AUTOSAR XML (schema 4.0)
standard types defined: float32, float64, sint16, sint32, sint8, uint16, uint32, uint8, void, boolean
package /ImplDataTypes
  7 x impl type, all with category=TYPE_REFERENCE, type-emitter=RTE:
    IoPositionSensorReadingType: implementation-data-type=uint8
    IoWeightSensorReadingType: implementation-data-type=uint16
    MultiStateBtnType: implementation-data-type=uint8
    SeatModeBtnType: implementation-data-type=uint8
    SensorPositionType: implementation-data-type=uint8
    SensorWeightType: implementation-data-type=uint8
    StepMotorStepType: implementation-data-type=uint8
package /MappingSets
  data type mapping set MappingSet: mode-request-type-map{implementation-data-type=uint8, mode-group=SeatCtrlMode}
package /PortInterfaces/ClientServer
  6 x client server interface:
    CsIf_IoGetSensorPosition
      operation IOGet
        arg IOPosition: type=IoPositionSensorReadingType, direction=OUT
    CsIf_IoGetSensorWeight
      operation IOGet
        arg IOWeight: type=IoWeightSensorReadingType, direction=OUT
    CsIf_IoSetMotor
      operation IOSetForward
      operation IOSetReverse
    CsIf_PositionSensor
      operation GetPosition
        arg Position: type=SensorPositionType, direction=OUT
    CsIf_StepMotor
      operation Move
        arg step: type=StepMotorStepType, direction=IN
    CsIf_WeightSensor
      operation GetWeight
        arg Weight: type=SensorWeightType, direction=OUT
package /PortInterfaces/ModeSwitch
  mode switch interface MsIf_SeatCtrlMode
    mode group SeatCtrlMode: type=SeatCtrlMode
  mode declaration group SeatCtrlMode: category=ALPHABETIC_ORDER, initial-mode=INIT, on-transition-value=255
    mode AUTO
    mode INIT
    mode MANUAL
package /PortInterfaces/SenderReceiver
  sender receiver interface SrIf_SeatCtrlBtns
    data HeightBtnState: type=MultiStateBtnType
    data InclineBtnState: type=MultiStateBtnType
    data SlideBtnState: type=MultiStateBtnType
  sender receiver interface SrIf_SeatCtrlData
    data Height: type=uint8
    data Incline: type=uint8
    data Slide: type=uint8
  sender receiver interface SrIf_SeatModeBtn
    data SeatModeBtn: type=SeatModeBtnType
package /SoftwareComponents
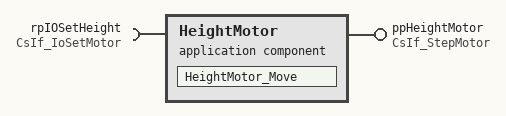
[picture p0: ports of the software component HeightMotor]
  application sw component type HeightMotor
    provide port ppHeightMotor: provided-interface=CsIf_StepMotor
    require port rpIOSetHeight: required-interface=CsIf_IoSetMotor
    behavior Ibhv_HeightMotor: data-type-mapping=MappingSet, handle-termination-and-restart=NO-SUPPORT
      operation invoked event OIE_ppHeightMotor_Move: start-on-event=HeightMotor_Move, operation=ppHeightMotor.Move
      runnable HeightMotor_Move
        sync call SCP_rpIOSetHeight_IOSetForward: operation=rpIOSetHeight.IOSetForward, timeout=0.0
        sync call SCP_rpIOSetHeight_IOSetReverse: operation=rpIOSetHeight.IOSetReverse, timeout=0.0
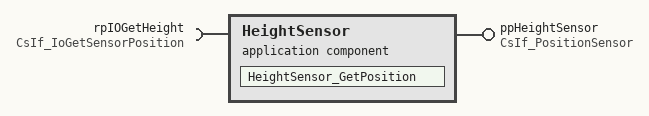
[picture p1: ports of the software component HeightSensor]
  application sw component type HeightSensor
    provide port ppHeightSensor: provided-interface=CsIf_PositionSensor
    require port rpIOGetHeight: required-interface=CsIf_IoGetSensorPosition
    behavior Ibhv_HeightSensor: data-type-mapping=MappingSet, handle-termination-and-restart=NO-SUPPORT
      operation invoked event OIE_ppHeightSensor_GetPosition: start-on-event=HeightSensor_GetPosition, operation=ppHeightSensor.GetPosition
      runnable HeightSensor_GetPosition
        sync call SCP_rpIOGetHeight_IOGet: operation=rpIOGetHeight.IOGet, timeout=0.0
  10 x swc implementation, all with programming-language=C, sw-version=1.0.0, vendor-id=255:
    Impl_HeightMotor: behavior=Ibhv_HeightMotor
      code-descriptors:
        code Code: artifact-descriptors=autosar-engineering-object={short-label=SWC.c, category=SWSRC}
      resource consumption ResourceConsumption
    Impl_HeightSensor: behavior=Ibhv_HeightSensor
      code-descriptors:
        code Code: artifact-descriptors=autosar-engineering-object={short-label=SWC.c, category=SWSRC}
      resource consumption ResourceConsumption
    Impl_InclineMotor: behavior=Ibhv_InclineMotor
      code-descriptors:
        code Code: artifact-descriptors=autosar-engineering-object={short-label=SWC.c, category=SWSRC}
      resource consumption ResourceConsumption
    Impl_InclineSensor: behavior=Ibhv_InclineSensor
      code-descriptors:
        code Code: artifact-descriptors=autosar-engineering-object={short-label=SWC.c, category=SWSRC}
      resource consumption ResourceConsumption
    Impl_IoHwAbs: behavior=Ibhv_IoHwAbs
      code-descriptors:
        code Code: artifact-descriptors=autosar-engineering-object={short-label=SWC.c, category=SWSRC}
      resource consumption ResourceConsumption
    Impl_SWC_HMI: behavior=Ibhv_SWC_HMI
      code-descriptors:
        code Code: artifact-descriptors=autosar-engineering-object={short-label=SWC.c, category=SWSRC}
      resource consumption ResourceConsumption
    Impl_SWC_SeatMngr: behavior=Ibhv_SWC_SeatMngr
      code-descriptors:
        code Code: artifact-descriptors=autosar-engineering-object={short-label=SWC.c, category=SWSRC}
      resource consumption ResourceConsumption
    Impl_SlideMotor: behavior=Ibhv_SlideMotor
      code-descriptors:
        code Code: artifact-descriptors=autosar-engineering-object={short-label=SWC.c, category=SWSRC}
      resource consumption ResourceConsumption
    Impl_SlideSensor: behavior=Ibhv_SlideSensor
      code-descriptors:
        code Code: artifact-descriptors=autosar-engineering-object={short-label=SWC.c, category=SWSRC}
      resource consumption ResourceConsumption
    Impl_WeightSensor: behavior=Ibhv_WeightSensor
      code-descriptors:
        code Code: artifact-descriptors=autosar-engineering-object={short-label=SWC.c, category=SWSRC}
      resource consumption ResourceConsumption
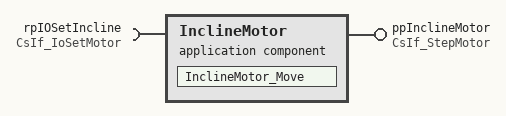
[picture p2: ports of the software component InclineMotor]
  application sw component type InclineMotor
    provide port ppInclineMotor: provided-interface=CsIf_StepMotor
    require port rpIOSetIncline: required-interface=CsIf_IoSetMotor
    behavior Ibhv_InclineMotor: data-type-mapping=MappingSet, handle-termination-and-restart=NO-SUPPORT
      operation invoked event OIE_ppInclineMotor_Move: start-on-event=InclineMotor_Move, operation=ppInclineMotor.Move
      runnable InclineMotor_Move
        sync call SCP_rpIOSetIncline_IOSetForward: operation=rpIOSetIncline.IOSetForward, timeout=0.0
        sync call SCP_rpIOSetIncline_IOSetReverse: operation=rpIOSetIncline.IOSetReverse, timeout=0.0
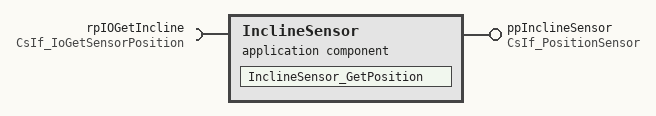
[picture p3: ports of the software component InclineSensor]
  application sw component type InclineSensor
    provide port ppInclineSensor: provided-interface=CsIf_PositionSensor
    require port rpIOGetIncline: required-interface=CsIf_IoGetSensorPosition
    behavior Ibhv_InclineSensor: data-type-mapping=MappingSet, handle-termination-and-restart=NO-SUPPORT
      operation invoked event OIE_ppInclineSensor_GetPosition: start-on-event=InclineSensor_GetPosition, operation=ppInclineSensor.GetPosition
      runnable InclineSensor_GetPosition
        sync call SCP_rpIOGetIncline_IOGet: operation=rpIOGetIncline.IOGet, timeout=0.0
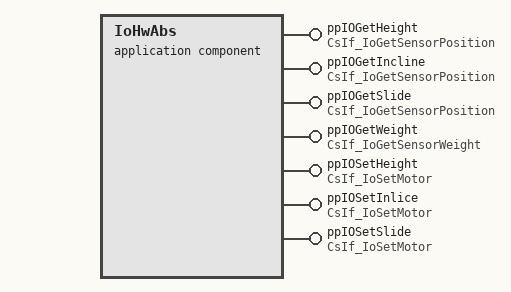
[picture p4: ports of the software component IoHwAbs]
  application sw component type IoHwAbs
    7 x provide port:
      ppIOGetHeight: provided-interface=CsIf_IoGetSensorPosition
      ppIOGetIncline: provided-interface=CsIf_IoGetSensorPosition
      ppIOGetSlide: provided-interface=CsIf_IoGetSensorPosition
      ppIOGetWeight: provided-interface=CsIf_IoGetSensorWeight
      ppIOSetHeight: provided-interface=CsIf_IoSetMotor
      ppIOSetInlice: provided-interface=CsIf_IoSetMotor
      ppIOSetSlide: provided-interface=CsIf_IoSetMotor
    behavior Ibhv_IoHwAbs: data-type-mapping=MappingSet, handle-termination-and-restart=NO-SUPPORT
      10 x operation invoked event:
        OIE_ppIOGetHeight_IOGet: start-on-event=IoHwAbs_ECUGetHeight, operation=ppIOGetHeight.IOGet
        OIE_ppIOGetIncline_IOGet: start-on-event=IoHwAbs_ECUGetIncline, operation=ppIOGetIncline.IOGet
        OIE_ppIOGetSlide_IOGet: start-on-event=IoHwAbs_ECUGetSlide, operation=ppIOGetSlide.IOGet
        OIE_ppIOGetWeight_IOGet: start-on-event=IoHwAbs_ECUGetWeight, operation=ppIOGetWeight.IOGet
        OIE_ppIOSetHeight_IOSetForward: start-on-event=IoHwAbs_ECUSetForward_Height, operation=ppIOSetHeight.IOSetForward
        OIE_ppIOSetHeight_IOSetReverse: start-on-event=IoHwAbs_ECUSetReverse_Height, operation=ppIOSetHeight.IOSetReverse
        OIE_ppIOSetInlice_IOSetForward: start-on-event=IoHwAbs_ECUSetForward_Incline, operation=ppIOSetInlice.IOSetForward
        OIE_ppIOSetInlice_IOSetReverse: start-on-event=IoHwAbs_ECUSetReverse_Incline, operation=ppIOSetInlice.IOSetReverse
        OIE_ppIOSetSlide_IOSetForward: start-on-event=IoHwAbs_ECUSetForward_Slide, operation=ppIOSetSlide.IOSetForward
        OIE_ppIOSetSlide_IOSetReverse: start-on-event=IoHwAbs_ECUSetReverse_Slide, operation=ppIOSetSlide.IOSetReverse
      10 x runnable:
        IoHwAbs_ECUGetHeight
        IoHwAbs_ECUGetIncline
        IoHwAbs_ECUGetSlide
        IoHwAbs_ECUGetWeight
        IoHwAbs_ECUSetForward_Height
        IoHwAbs_ECUSetForward_Incline
        IoHwAbs_ECUSetForward_Slide
        IoHwAbs_ECUSetReverse_Height
        IoHwAbs_ECUSetReverse_Incline
        IoHwAbs_ECUSetReverse_Slide
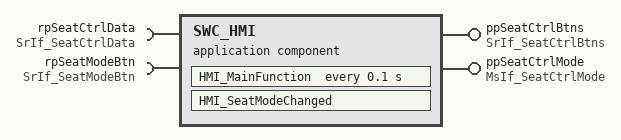
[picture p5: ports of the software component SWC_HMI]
  application sw component type SWC_HMI
    provide port ppSeatCtrlBtns: provided-interface=SrIf_SeatCtrlBtns
    provide port ppSeatCtrlMode: provided-interface=MsIf_SeatCtrlMode
    require port rpSeatCtrlData: required-interface=SrIf_SeatCtrlData
    require port rpSeatModeBtn: required-interface=SrIf_SeatModeBtn
    behavior Ibhv_SWC_HMI: data-type-mapping=MappingSet, handle-termination-and-restart=NO-SUPPORT
      data received event DRE_rpSeatModeBtn_SeatModeBtn: start-on-event=HMI_SeatModeChanged, data=rpSeatModeBtn.SeatModeBtn
      timing event TE_HMI_MainFunction_100ms: start-on-event=HMI_MainFunction, period=0.1
      runnable HMI_MainFunction
        data-receive-point-by-arguments:
          access DRP_rpSeatCtrlData_DE_Height: accessed-variable=rpSeatCtrlData.Height
          access DRP_rpSeatCtrlData_DE_Incline: accessed-variable=rpSeatCtrlData.Incline
          access DRP_rpSeatCtrlData_DE_Slide: accessed-variable=rpSeatCtrlData.Slide
        data-send-points:
          access DSP_ppSeatCtrlBtns_DE_HeightBtnState: accessed-variable=ppSeatCtrlBtns.HeightBtnState
          access DSP_ppSeatCtrlBtns_DE_InclineBtnState: accessed-variable=ppSeatCtrlBtns.InclineBtnState
          access DSP_ppSeatCtrlBtns_DE_SlideBtnState: accessed-variable=ppSeatCtrlBtns.SlideBtnState
      runnable HMI_SeatModeChanged
        data-receive-point-by-arguments:
          access DRP_rpSeatModeBtn_SeatModeBtn: accessed-variable=rpSeatModeBtn.SeatModeBtn
        mode switch point MSP_ppSeatCtrlMode_ppSeatCtrlMode: mode-group=ppSeatCtrlMode.SeatCtrlMode
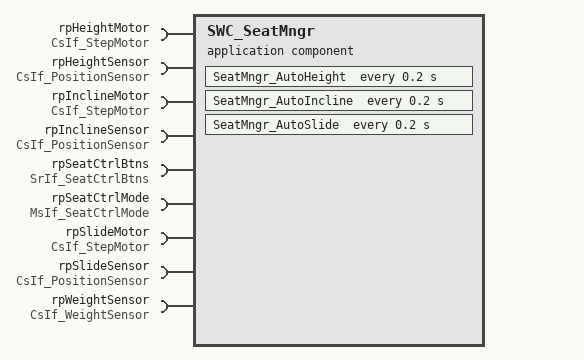
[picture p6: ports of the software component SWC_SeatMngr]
  application sw component type SWC_SeatMngr
    9 x require port:
      rpHeightMotor: required-interface=CsIf_StepMotor
      rpHeightSensor: required-interface=CsIf_PositionSensor
      rpInclineMotor: required-interface=CsIf_StepMotor
      rpInclineSensor: required-interface=CsIf_PositionSensor
      rpSeatCtrlBtns: required-interface=SrIf_SeatCtrlBtns
      rpSeatCtrlMode: required-interface=MsIf_SeatCtrlMode
      rpSlideMotor: required-interface=CsIf_StepMotor
      rpSlideSensor: required-interface=CsIf_PositionSensor
      rpWeightSensor: required-interface=CsIf_WeightSensor
    behavior Ibhv_SWC_SeatMngr: data-type-mapping=MappingSet, handle-termination-and-restart=NO-SUPPORT
      data received event DRE_rpSeatCtrlBtns_DE_HeightBtnState: start-on-event=SeatMngr_SetHeight, data=rpSeatCtrlBtns.DE_HeightBtnState
      data received event DRE_rpSeatCtrlBtns_DE_InclineBtnState: start-on-event=SeatMngr_SetIncline, data=rpSeatCtrlBtns.DE_InclineBtnState
      data received event DRE_rpSeatCtrlBtns_DE_SlideBtnState: start-on-event=SeatMngr_SetSlide, data=rpSeatCtrlBtns.DE_SlideBtnState
      timing event TE_SeatMngr_AutoHeight_200ms: start-on-event=SeatMngr_AutoHeight, period=0.2
      timing event TE_SeatMngr_AutoIncline_200ms: start-on-event=SeatMngr_AutoIncline, period=0.2
      timing event TE_SeatMngr_AutoSlide_200ms: start-on-event=SeatMngr_AutoSlide, period=0.2
      6 x runnable:
        SeatMngr_AutoHeight
          sync call SCP_rpHeightMotor_Move: operation=rpHeightMotor.Move, timeout=0.0
          sync call SCP_rpHeightSensor_GetPosition: operation=rpHeightSensor.GetPosition, timeout=0.0
          sync call SCP_rpWeightSensor_GetWeight: operation=rpWeightSensor.GetWeight, timeout=0.0
        SeatMngr_AutoIncline
          sync call SCP_rpInclineMotor_Move: operation=rpInclineMotor.Move, timeout=0.0
          sync call SCP_rpInclineSensor_GetPosition: operation=rpInclineSensor.GetPosition, timeout=0.0
          sync call SCP_rpWeightSensor_GetWeight: operation=rpWeightSensor.GetWeight, timeout=0.0
        SeatMngr_AutoSlide
          sync call SCP_rpSlideMotor_Move: operation=rpSlideMotor.Move, timeout=0.0
          sync call SCP_rpSlideSensor_GetPosition: operation=rpSlideSensor.GetPosition, timeout=0.0
          sync call SCP_rpWeightSensor_GetWeight: operation=rpWeightSensor.GetWeight, timeout=0.0
        SeatMngr_SetHeight
          data-receive-point-by-arguments:
            access DRP_rpSeatCtrlBtns_DE_HeightBtnState: accessed-variable=rpSeatCtrlBtns.HeightBtnState
          sync call SCP_rpHeightMotor_Move: operation=rpHeightMotor.Move, timeout=0.0
        SeatMngr_SetIncline
          data-receive-point-by-arguments:
            access DRP_rpSeatCtrlBtns_DE_InclineBtnState: accessed-variable=rpSeatCtrlBtns.InclineBtnState
          sync call SCP_rpInclineMotor_Move: operation=rpInclineMotor.Move, timeout=0.0
        SeatMngr_SetSlide
          data-receive-point-by-arguments:
            access DRP_rpSeatCtrlBtns_DE_SlideBtnState: accessed-variable=rpSeatCtrlBtns.SlideBtnState
          sync call SCP_rpSlideMotor_Move: operation=rpSlideMotor.Move, timeout=0.0
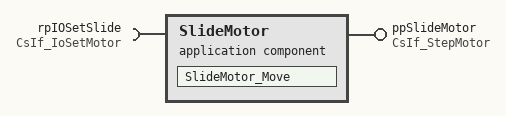
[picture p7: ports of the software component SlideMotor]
  application sw component type SlideMotor
    provide port ppSlideMotor: provided-interface=CsIf_StepMotor
    require port rpIOSetSlide: required-interface=CsIf_IoSetMotor
    behavior Ibhv_SlideMotor: data-type-mapping=MappingSet, handle-termination-and-restart=NO-SUPPORT
      operation invoked event OIE_ppSlideMotor_Move: start-on-event=SlideMotor_Move, operation=ppSlideMotor.Move
      runnable SlideMotor_Move
        sync call SCP_rpIOSetSlide_IOSetForward: operation=rpIOSetSlide.IOSetForward, timeout=0.0
        sync call SCP_rpIOSetSlide_IOSetReverse: operation=rpIOSetSlide.IOSetReverse, timeout=0.0
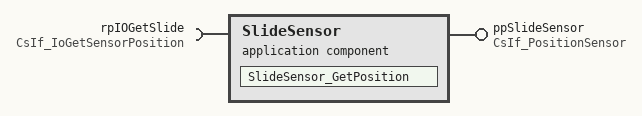
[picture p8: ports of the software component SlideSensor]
  application sw component type SlideSensor
    provide port ppSlideSensor: provided-interface=CsIf_PositionSensor
    require port rpIOGetSlide: required-interface=CsIf_IoGetSensorPosition
    behavior Ibhv_SlideSensor: data-type-mapping=MappingSet, handle-termination-and-restart=NO-SUPPORT
      operation invoked event OIE_ppSlideSensor_GetPosition: start-on-event=SlideSensor_GetPosition, operation=ppSlideSensor.GetPosition
      runnable SlideSensor_GetPosition
        sync call SCP_rpIOGetSlide_IOGet: operation=rpIOGetSlide.IOGet, timeout=0.0
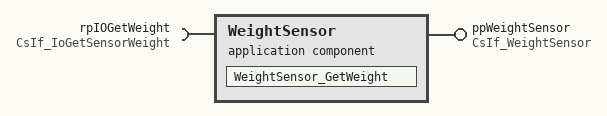
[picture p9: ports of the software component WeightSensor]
  application sw component type WeightSensor
    provide port ppWeightSensor: provided-interface=CsIf_WeightSensor
    require port rpIOGetWeight: required-interface=CsIf_IoGetSensorWeight
    behavior Ibhv_WeightSensor: data-type-mapping=MappingSet, handle-termination-and-restart=NO-SUPPORT
      operation invoked event OIE_ppWeightSensor_GetWeight: start-on-event=WeightSensor_GetWeight, operation=ppWeightSensor.GetWeight
      runnable WeightSensor_GetWeight
        sync call SCP_rpIOGetWeight_IOGet: operation=rpIOGetWeight.IOGet, timeout=0.0
package /Compositions
  composition sw component type SeatControlComposition
    10 x component:
      HeightMotor: type=HeightMotor
      HeightSensor: type=HeightSensor
      InclineMotor: type=InclineMotor
      InclineSensor: type=InclineSensor
      IoHwAbs: type=IoHwAbs
      SWC_HMI: type=SWC_HMI
      SWC_SeatMngr: type=SWC_SeatMngr
      SlideMotor: type=SlideMotor
      SlideSensor: type=SlideSensor
      WeightSensor: type=WeightSensor
    connect HeightMotor.ppHeightMotor -> SWC_SeatMngr.rpHeightMotor
    connect HeightSensor.ppHeightSensor -> SWC_SeatMngr.rpHeightSensor
    connect InclineMotor.ppInclineMotor -> SWC_SeatMngr.rpInclineMotor
    connect InclineSensor.ppInclineSensor -> SWC_SeatMngr.rpInclineSensor
    connect IoHwAbs.ppIOGetHeight -> HeightSensor.rpIOGetHeight
    connect IoHwAbs.ppIOGetIncline -> InclineSensor.rpIOGetIncline
    connect IoHwAbs.ppIOGetSlide -> SlideSensor.rpIOGetSlide
    connect IoHwAbs.ppIOGetWeight -> WeightSensor.rpIOGetWeight
    connect IoHwAbs.ppIOSetHeight -> HeightMotor.rpIOSetHeight
    connect IoHwAbs.ppIOSetInlice -> InclineMotor.rpIOSetIncline
    connect IoHwAbs.ppIOSetSlide -> SlideMotor.rpIOSetSlide
    connect SWC_HMI.ppSeatCtrlBtns -> SWC_SeatMngr.rpSeatCtrlBtns
    connect SWC_HMI.ppSeatCtrlMode -> SWC_SeatMngr.rpSeatCtrlMode
    connect SlideMotor.ppSlideMotor -> SWC_SeatMngr.rpSlideMotor
    connect SlideSensor.ppSlideSensor -> SWC_SeatMngr.rpSlideSensor
    connect WeightSensor.ppWeightSensor -> SWC_SeatMngr.rpWeightSensor
